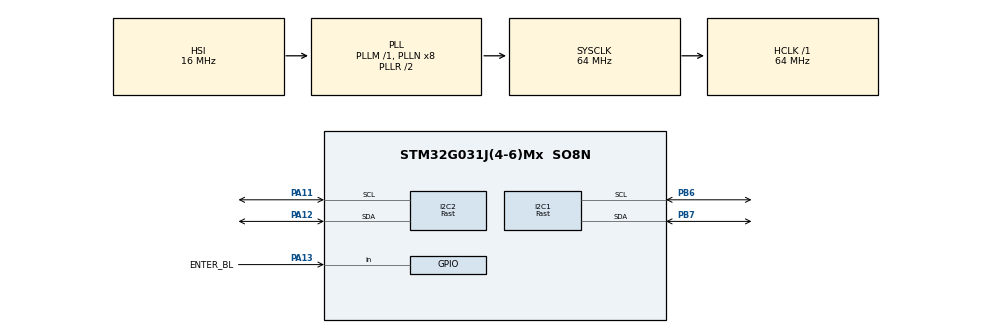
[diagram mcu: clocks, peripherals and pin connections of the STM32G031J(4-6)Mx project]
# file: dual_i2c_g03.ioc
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I2C1.I2C_Speed_Mode=I2C_Fast
I2C1.NoStretchMode=I2C_NOSTRETCH_ENABLE
I2C1.OwnAddress=0x38
I2C1.Timing=0x00C12166
I2C2.I2C_Speed_Mode=I2C_Fast
I2C2.NoStretchMode=I2C_NOSTRETCH_ENABLE
I2C2.Timing=0x00C12166
Mcu.Family=STM32G0
Mcu.Name=STM32G031J(4-6)Mx
Mcu.Package=SO8N
NVIC.I2C1_IRQn=true\:0\:0\:false\:false\:true\:true\:true\:true
PA11\ [PA9].Mode=I2C
PA11\ [PA9].Signal=I2C2_SCL
PA12\ [PA10].Mode=I2C
PA12\ [PA10].Signal=I2C2_SDA
PA13.GPIO_Label=ENTER_BL
PA13.GPIO_PuPd=GPIO_PULLUP
PA13.Signal=GPIO_Input
PA14-BOOT0__PA15__PB5__PB6.StandardMode=true
PB0__PB1__PA8__PA11\ [PA9].StandardMode=true
PB6.GPIO_FM6=__NULL
PB6.Mode=I2C
PB6.Signal=I2C1_SCL
PB7.GPIO_FM7=__NULL
PB7.Mode=I2C
PB7.Signal=I2C1_SDA
PC14-OSC32_IN\ (PC14)__PB7__PB8__PB9.StandardMode=true
PF2\ -\ NRST__PA0__PA1__PA2.StandardMode=true
ProjectManager.HeapSize=0x200
ProjectManager.StackSize=0x400
ProjectManager.TargetToolchain=Makefile
RCC.ADCFreq_Value=64000000
RCC.AHBFreq_Value=64000000
RCC.CortexFreq_Value=64000000
RCC.EXTERNAL_CLOCK_VALUE=12288000
RCC.HCLKFreq_Value=64000000
RCC.HSE_VALUE=8000000
RCC.HSI_VALUE=16000000
RCC.LSE_VALUE=32768
RCC.SYSCLKFreq_VALUE=64000000
RCC.SYSCLKSource=RCC_SYSCLKSOURCE_PLLCLK
RCC.VCOOutputFreq_Value=128000000
board=custom

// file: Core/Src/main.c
/* USER CODE BEGIN Header */
/**
  ******************************************************************************
  * @file           : main.c
  * @brief          : Main program body
  ******************************************************************************
  * @attention
  *
  * Copyright (c) 2025 STMicroelectronics.
  * All rights reserved.
  *
  * This software is licensed under terms that can be found in the LICENSE file
  * in the root directory of this software component.
  * If no LICENSE file comes with this software, it is provided AS-IS.
  *
  ******************************************************************************
  */
/* USER CODE END Header */
#include "main.h"

/* USER CODE BEGIN Includes */
#include "display.h"
#include "slave.h"
/* USER CODE END Includes */

I2C_HandleTypeDef hi2c1;
I2C_HandleTypeDef hi2c2;

void SystemClock_Config(void);
static void MX_GPIO_Init(void);
static void MX_I2C1_Init(void);
static void MX_I2C2_Init(void);

int main(void)
{

  /* MCU Configuration--------------------------------------------------------*/

  /* Reset of all peripherals, Initializes the Flash interface and the Systick. */
  HAL_Init();

  /* Configure the system clock */
  SystemClock_Config();

  /* Initialize all configured peripherals */
  MX_GPIO_Init();
  MX_I2C1_Init();
  MX_I2C2_Init();
  /* USER CODE BEGIN 2 */
  Display_Init();
  Slave_Init();
  /* USER CODE END 2 */

  /* Infinite loop */
  /* USER CODE BEGIN WHILE */
  while (1)
  {
    Display_Tick();
    /* USER CODE END WHILE */

  }
}

void SystemClock_Config(void)
{
  RCC_OscInitTypeDef RCC_OscInitStruct = {0};
  RCC_ClkInitTypeDef RCC_ClkInitStruct = {0};

  /** Configure the main internal regulator output voltage
  */
  HAL_PWREx_ControlVoltageScaling(PWR_REGULATOR_VOLTAGE_SCALE1);

  /** Initializes the RCC Oscillators according to the specified parameters
  * in the RCC_OscInitTypeDef structure.
  */
  RCC_OscInitStruct.OscillatorType = RCC_OSCILLATORTYPE_HSI;
  RCC_OscInitStruct.HSIState = RCC_HSI_ON;
  RCC_OscInitStruct.HSIDiv = RCC_HSI_DIV1;
  RCC_OscInitStruct.HSICalibrationValue = RCC_HSICALIBRATION_DEFAULT;
  RCC_OscInitStruct.PLL.PLLState = RCC_PLL_ON;
  RCC_OscInitStruct.PLL.PLLSource = RCC_PLLSOURCE_HSI;
  RCC_OscInitStruct.PLL.PLLM = RCC_PLLM_DIV1;
  RCC_OscInitStruct.PLL.PLLN = 8;
  RCC_OscInitStruct.PLL.PLLP = RCC_PLLP_DIV2;
  RCC_OscInitStruct.PLL.PLLQ = RCC_PLLQ_DIV2;
  RCC_OscInitStruct.PLL.PLLR = RCC_PLLR_DIV2;
  if (HAL_RCC_OscConfig(&RCC_OscInitStruct) != HAL_OK)
  {
    Error_Handler();
  }

  /** Initializes the CPU, AHB and APB buses clocks
  */
  RCC_ClkInitStruct.ClockType = RCC_CLOCKTYPE_HCLK|RCC_CLOCKTYPE_SYSCLK
                              |RCC_CLOCKTYPE_PCLK1;
  RCC_ClkInitStruct.SYSCLKSource = RCC_SYSCLKSOURCE_PLLCLK;
  RCC_ClkInitStruct.AHBCLKDivider = RCC_SYSCLK_DIV1;
  RCC_ClkInitStruct.APB1CLKDivider = RCC_HCLK_DIV1;

  if (HAL_RCC_ClockConfig(&RCC_ClkInitStruct, FLASH_LATENCY_2) != HAL_OK)
  {
    Error_Handler();
  }
}

static void MX_I2C1_Init(void)
{

  hi2c1.Instance = I2C1;
  hi2c1.Init.Timing = 0x00C12166;
  hi2c1.Init.OwnAddress1 = 112;
  hi2c1.Init.AddressingMode = I2C_ADDRESSINGMODE_7BIT;
  hi2c1.Init.DualAddressMode = I2C_DUALADDRESS_DISABLE;
  hi2c1.Init.OwnAddress2 = 0;
  hi2c1.Init.OwnAddress2Masks = I2C_OA2_NOMASK;
  hi2c1.Init.GeneralCallMode = I2C_GENERALCALL_DISABLE;
  hi2c1.Init.NoStretchMode = I2C_NOSTRETCH_ENABLE;
  if (HAL_I2C_Init(&hi2c1) != HAL_OK)
  {
    Error_Handler();
  }

  /** Configure Analogue filter
  */
  if (HAL_I2CEx_ConfigAnalogFilter(&hi2c1, I2C_ANALOGFILTER_ENABLE) != HAL_OK)
  {
    Error_Handler();
  }

  /** Configure Digital filter
  */
  if (HAL_I2CEx_ConfigDigitalFilter(&hi2c1, 0) != HAL_OK)
  {
    Error_Handler();
  }

}

static void MX_I2C2_Init(void)
{

  hi2c2.Instance = I2C2;
  hi2c2.Init.Timing = 0x00C12166;
  hi2c2.Init.OwnAddress1 = 0;
  hi2c2.Init.AddressingMode = I2C_ADDRESSINGMODE_7BIT;
  hi2c2.Init.DualAddressMode = I2C_DUALADDRESS_DISABLE;
  hi2c2.Init.OwnAddress2 = 0;
  hi2c2.Init.OwnAddress2Masks = I2C_OA2_NOMASK;
  hi2c2.Init.GeneralCallMode = I2C_GENERALCALL_DISABLE;
  hi2c2.Init.NoStretchMode = I2C_NOSTRETCH_ENABLE;
  if (HAL_I2C_Init(&hi2c2) != HAL_OK)
  {
    Error_Handler();
  }

  /** Configure Analogue filter
  */
  if (HAL_I2CEx_ConfigAnalogFilter(&hi2c2, I2C_ANALOGFILTER_ENABLE) != HAL_OK)
  {
    Error_Handler();
  }

  /** Configure Digital filter
  */
  if (HAL_I2CEx_ConfigDigitalFilter(&hi2c2, 0) != HAL_OK)
  {
    Error_Handler();
  }

}

static void MX_GPIO_Init(void)
{

  /* GPIO Ports Clock Enable */
  __HAL_RCC_GPIOB_CLK_ENABLE();
  __HAL_RCC_GPIOA_CLK_ENABLE();

}

void Error_Handler(void)
{
  __disable_irq();
  while (1)
  {
  }
}
